# RL6955_IP_SVD register map
Vendor: Realtek
Registers are 32-bit, read-write, reset 0x0 unless marked. A register's access mark holds for its fields unless they carry their own. Offsets are from the block's base; [hi:lo] are bit positions; {n}, {i} and the like mark numbered series; <NAME> marks a mode.

## CAN0_REG
Base 0x41803000
Same registers: CAN1_REG 0x41804000
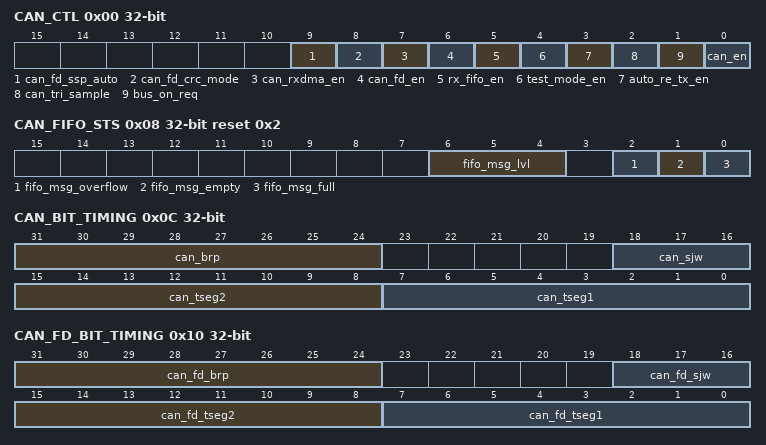
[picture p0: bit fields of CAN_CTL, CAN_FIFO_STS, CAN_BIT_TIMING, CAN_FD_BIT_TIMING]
0x00 CAN_CTL — CAN bus control register
  [9] can_fd_ssp_auto — automatic calculat ssp delay, ssp = second sample point
  [8] can_fd_crc_mode — crc mode select * 0: ISO crc * 1: non-ISO crc
  [7] can_rxdma_en — rx dma enable
  [6] can_fd_en — enable CAN FD protocol
  [5] rx_fifo_en — rx fifo function enable
  [4] test_mode_en — test mode enable, for lbk or silent mode use
  [3] auto_re_tx_en — auto re-transmission enabled
  [2] can_tri_sample — triple sample mode
  [1] bus_on_req — request to bus_on
  [0] can_en — can enable
0x04 CAN_STS ro — CAN bus status
  [0] bus_on_state — bus state * 1 means the can module is already bus on * 0 means the can module is busoff
0x08 CAN_FIFO_STS ro reset 0x2 — CAN bus FIFO status
  [6:4] fifo_msg_lvl — rx fifo message level
  [2] fifo_msg_overflow — rx fifo overflow
  [1] fifo_msg_empty — rx fifo empty
  [0] fifo_msg_full — rx fifo full
0x0C CAN_BIT_TIMING — CAN2.0 bit timing
  [31:24] can_brp — CAN bit timing perscaler = <$bit:can_brp>+1
  [18:16] can_sjw — SJW length = <$bit:can_sjw>
  [15:8] can_tseg2 — TSEG2 length = <$bit:can_tseg2+1>
  [7:0] can_tseg1 — TSEG1 length = <$bit:can_tseg1+1>
0x10 CAN_FD_BIT_TIMING — CAN FD DATA field bit timing
  [31:24] can_fd_brp — CAN bit timing perscaler = <$bit:can_fd_brp>+1
  [18:16] can_fd_sjw — SJW length = <$bit:can_fd_sjw>
  [15:8] can_fd_tseg2 — TSEG2 length = <$bit:can_fd_tseg2+1>
  [7:0] can_fd_tseg1 — TSEG1 length = <$bit:can_fd_tseg1>+1
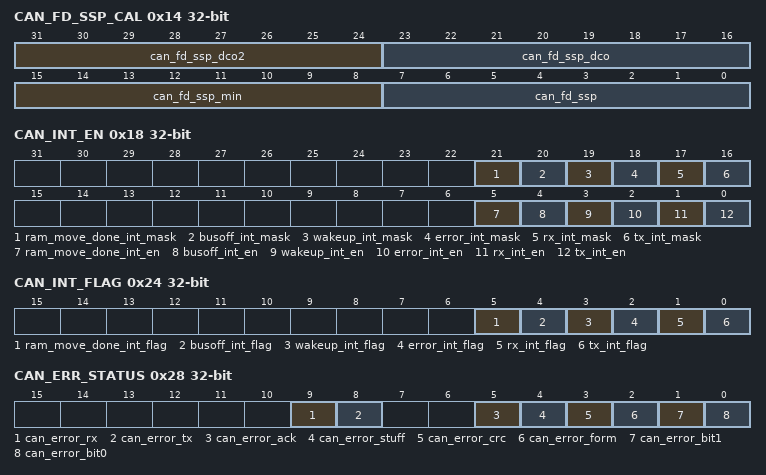
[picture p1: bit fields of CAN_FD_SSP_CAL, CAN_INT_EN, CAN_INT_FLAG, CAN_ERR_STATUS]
0x14 CAN_FD_SSP_CAL — CAN FD SSP configuration
  [31:24] can_fd_ssp_dco2 — delay compensation offset2
  [23:16] can_fd_ssp_dco — delay compensation offset
  [15:8] can_fd_ssp_min — minimum of ssp from start of one bit, only functional when can_fd_ssp_auto set
  [7:0] can_fd_ssp — ssp position, delay from start of one bit, if automatic calculation is enabled, the field will update after calculation
0x18 CAN_INT_EN — CAN interrupt control
  [21] ram_move_done_int_mask — ram move done interrupt mask 1: mask 0: unmask
  [20] busoff_int_mask — wakeup interrupt mask 1: mask 0: unmask
  [19] wakeup_int_mask — wakeup interrupt mask 1: mask 0: unmask
  [18] error_int_mask — error interrupt mask 1: mask 0: unmask
  [17] rx_int_mask — rx interrupt mask 1: mask 0: unmask
  [16] tx_int_mask — tx interrupt mask 1: mask 0: unmask
  [5] ram_move_done_int_en — ram move done interrupt enable
  [4] busoff_int_en — wakeup interrupt enbale
  [3] wakeup_int_en — wakeup interrupt enbale
  [2] error_int_en — error interrupt enable
  [1] rx_int_en — rx interrupt enable
  [0] tx_int_en — tx interrupt enable
0x1C CAN_MB_RXINT_EN — CAN rx interrupt for message buffers
  [15:0] can_mb_rxint_en — rx interrupt enable for each message buffer
0x20 CAN_MB_TXINT_EN — CAN tx interrupt for message buffers
  [15:0] can_mb_txint_en — tx interrupt enable for each message buffer
0x24 CAN_INT_FLAG ro — CAN interrupt flags
  [5] ram_move_done_int_flag — data move from register to CAN IP internal RAM finished interupt, move from RAM to register done will NOT generate interrupt, write one to clear
  [4] busoff_int_flag — busoff interrupt flag, write one to clear
  [3] wakeup_int_flag — wakeup interrupt flag, write one to clear
  [2] error_int_flag — error interrupt flag, write to clear
  [1] rx_int_flag — rx interrupt flag, write to clear
  [0] tx_int_flag — tx interrupt flag, write to clear
0x28 CAN_ERR_STATUS ro — CAN error status
  [9] can_error_rx — can rx error flag
  [8] can_error_tx — can tx error flag
  [5] can_error_ack — latest error is ack error
  [4] can_error_stuff — latest error is stuff error
  [3] can_error_crc — latest error is ctc error
  [2] can_error_form — latest error is form error
  [1] can_error_bit1 — latest error is bit1 error, tx=1 but rx=0
  [0] can_error_bit0 — latest error is bit0 error, tx=0 but rx=1
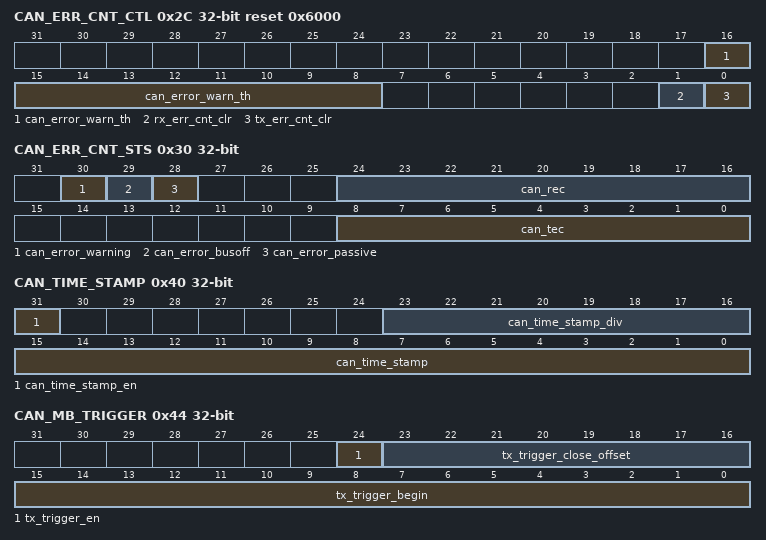
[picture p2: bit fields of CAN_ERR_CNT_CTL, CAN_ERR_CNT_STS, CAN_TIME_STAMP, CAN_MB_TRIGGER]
0x2C CAN_ERR_CNT_CTL access per field reset 0x6000 — CAN bus error counter control
  [16:8] can_error_warn_th rw — error counter warning threshold, programable, default 96. NOTES: 0~127 is availaible to both TEC and REC, 128~255 is only available to TEC
  [1] rx_err_cnt_clr wo — write 1 to clear can_rec
  [0] tx_err_cnt_clr wo — write 1 to clear can_tec
0x30 CAN_ERR_CNT_STS ro — CAN bus error counter status
  [30] can_error_warning — error counter arrive at warning threshold
  [29] can_error_busoff — error counter arrive at bus off level
  [28] can_error_passive — error counter arrive at error passive level
  [24:16] can_rec — receive error count
  [8:0] can_tec — transmit error count
0x34 CAN_TX_ERROR_FLAG ro — CAN tx error flag for each message buffe
  [15:0] can_tx_error_flag — indicate which message tx buffer have error detected, cpu can write 1 to clear
0x38 CAN_TX_DONE ro — CAN tx done for message buffers
  [15:0] can_tx_done — tx done for each message buffer
0x3C CAN_RX_DONE ro — CAN rx done for message buffers
  [15:0] can_rx_done — rx done for each message buffer
0x40 CAN_TIME_STAMP access per field — Timestamp function
  [31] can_time_stamp_en rw — time stamp function enable and time stamp counter start
  [23:16] can_time_stamp_div rw — timer stamp conter prescalar
  [15:0] can_time_stamp ro — time stamp counter value, up count
0x44 CAN_MB_TRIGGER — CAN tx trigger by timer configuration
  [24] tx_trigger_en — End of message buffer base address in RAM
  [23:16] tx_trigger_close_offset — end of trigger time = <$bit:tx_trigger_begin> + <$bit:tx_trigger_close_offset>
  [15:0] tx_trigger_begin — start of trigger time
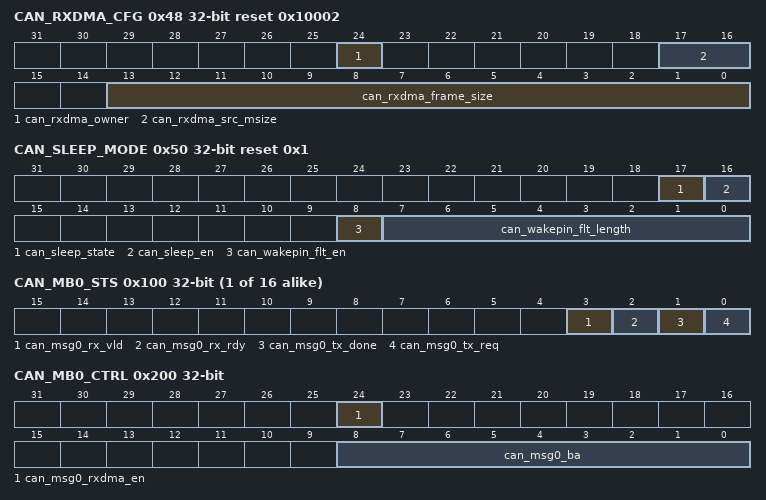
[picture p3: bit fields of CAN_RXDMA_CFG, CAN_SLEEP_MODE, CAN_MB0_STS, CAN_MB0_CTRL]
0x48 CAN_RXDMA_CFG access per field reset 0x10002 — RX dma configuration
  [24] can_rxdma_owner rw — can rxdma owner is : 0:GDMA 1:CAN
  [17:16] can_rxdma_src_msize rw — rx dma burst size: 'b00: dma burst size=1 'b01: dma burst size=4 'b10: dma burst size=8 'b11: dma burst size=16
  [13:0] can_rxdma_frame_size ro — can rx dma data frame size = ceil(<rx_dma_data bytes number>/4 ), for example: rx_dma_data is 9~12 bytes, frame size is 3
0x4C CAN_RX_DMA_DATA ro — Register for dma access message buffe
  [31:0] can_rx_dma_data — For DMA read received data
0x50 CAN_SLEEP_MODE access per field reset 0x1 — sleep mode request and wakeup pin digital filter
  [17] can_sleep_state ro — can is sleep or not 1: is 0: isn't
  [16] can_sleep_en rw — can sleep enable 1:request can to sleep mode 0:wakeup can
  [8] can_wakepin_flt_en rw — wakeup pin digital filter enable
  [7:0] can_wakepin_flt_length rw — wakeup pin digital filter length
0x54 CAN_TEST — test configuration
  [1:0] can_test_cfg — 2b'00: silence_mode 2b'01: external loopback mode (enable can_tx_so ) 2b'10: internal loopback mode (can_tx_so tie 1) 2b'11: reserved
{0x100+4i} CAN_MB{i}_STS ro (i=0..15)
  [3] can_msg{i}_rx_vld — new message have been received in the message buffer
  [2] can_msg{i}_rx_rdy — the message buffer is ready for receiving a new message
  [1] can_msg{i}_tx_done — tx message in the message buffer finish sending
  [0] can_msg{i}_tx_req — tx message is pending for transmit
0x200 CAN_MB0_CTRL
  [24] can_msg0_rxdma_en — dma enable when the message buffer used as rx
  [8:0] can_msg0_ba — message buffer base address in RAM
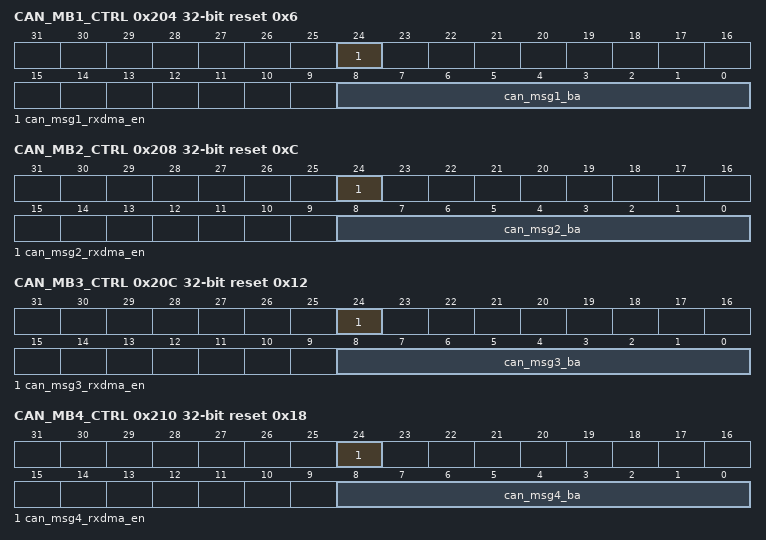
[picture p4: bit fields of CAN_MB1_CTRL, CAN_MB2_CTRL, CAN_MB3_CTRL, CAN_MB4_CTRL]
0x204 CAN_MB1_CTRL reset 0x6
  [24] can_msg1_rxdma_en — dma enable when the message buffer used as rx
  [8:0] can_msg1_ba — message buffer base address in RAM
0x208 CAN_MB2_CTRL reset 0xC
  [24] can_msg2_rxdma_en — dma enable when the message buffer used as rx
  [8:0] can_msg2_ba — message buffer base address in RAM
0x20C CAN_MB3_CTRL reset 0x12
  [24] can_msg3_rxdma_en — dma enable when the message buffer used as rx
  [8:0] can_msg3_ba — message buffer base address in RAM
0x210 CAN_MB4_CTRL reset 0x18
  [24] can_msg4_rxdma_en — dma enable when the message buffer used as rx
  [8:0] can_msg4_ba — message buffer base address in RAM
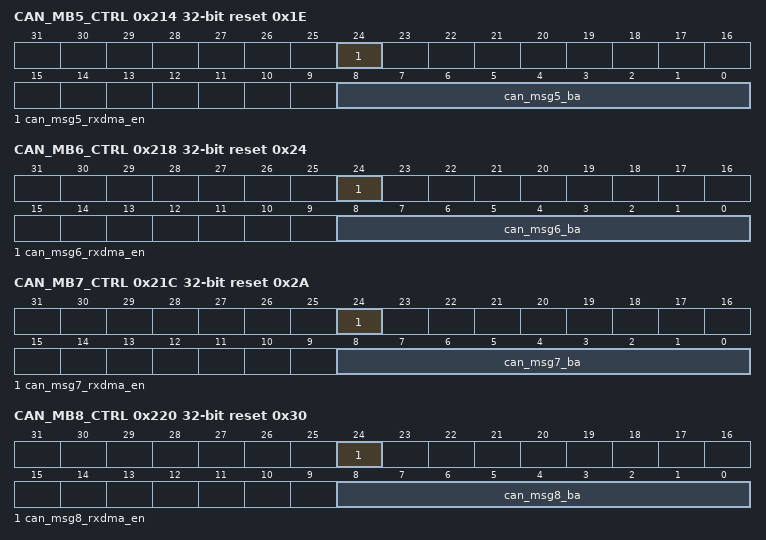
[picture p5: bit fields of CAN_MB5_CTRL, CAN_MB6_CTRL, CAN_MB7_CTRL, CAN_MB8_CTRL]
0x214 CAN_MB5_CTRL reset 0x1E
  [24] can_msg5_rxdma_en — dma enable when the message buffer used as rx
  [8:0] can_msg5_ba — message buffer base address in RAM
0x218 CAN_MB6_CTRL reset 0x24
  [24] can_msg6_rxdma_en — dma enable when the message buffer used as rx
  [8:0] can_msg6_ba — message buffer base address in RAM
0x21C CAN_MB7_CTRL reset 0x2A
  [24] can_msg7_rxdma_en — dma enable when the message buffer used as rx
  [8:0] can_msg7_ba — message buffer base address in RAM
0x220 CAN_MB8_CTRL reset 0x30
  [24] can_msg8_rxdma_en — dma enable when the message buffer used as rx
  [8:0] can_msg8_ba — message buffer base address in RAM
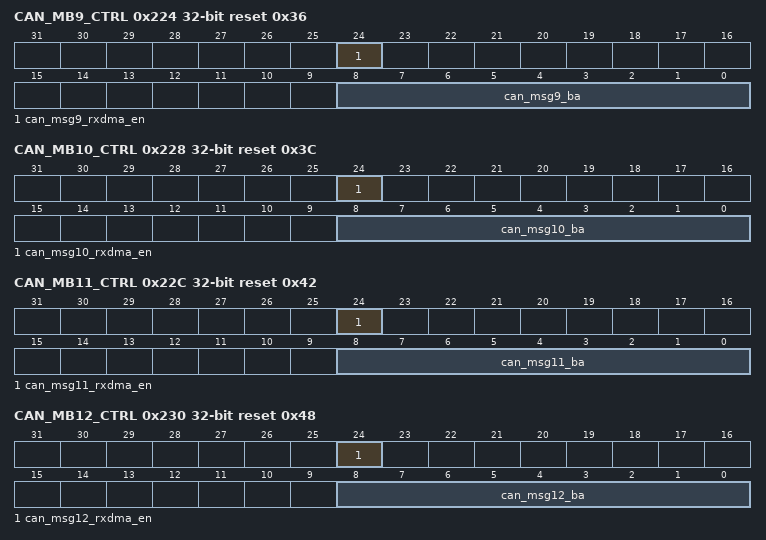
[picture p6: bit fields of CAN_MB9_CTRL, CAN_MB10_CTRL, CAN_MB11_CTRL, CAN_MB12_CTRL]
0x224 CAN_MB9_CTRL reset 0x36
  [24] can_msg9_rxdma_en — dma enable when the message buffer used as rx
  [8:0] can_msg9_ba — message buffer base address in RAM
0x228 CAN_MB10_CTRL reset 0x3C
  [24] can_msg10_rxdma_en — dma enable when the message buffer used as rx
  [8:0] can_msg10_ba — message buffer base address in RAM
0x22C CAN_MB11_CTRL reset 0x42
  [24] can_msg11_rxdma_en — dma enable when the message buffer used as rx
  [8:0] can_msg11_ba — message buffer base address in RAM
0x230 CAN_MB12_CTRL reset 0x48
  [24] can_msg12_rxdma_en — dma enable when the message buffer used as rx
  [8:0] can_msg12_ba — message buffer base address in RAM
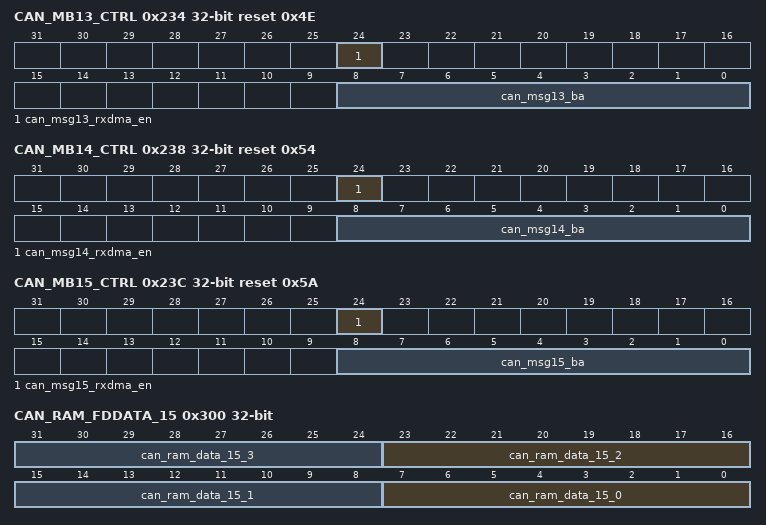
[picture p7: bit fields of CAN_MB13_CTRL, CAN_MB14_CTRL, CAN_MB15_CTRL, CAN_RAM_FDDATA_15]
0x234 CAN_MB13_CTRL reset 0x4E
  [24] can_msg13_rxdma_en — dma enable when the message buffer used as rx
  [8:0] can_msg13_ba — message buffer base address in RAM
0x238 CAN_MB14_CTRL reset 0x54
  [24] can_msg14_rxdma_en — dma enable when the message buffer used as rx
  [8:0] can_msg14_ba — message buffer base address in RAM
0x23C CAN_MB15_CTRL reset 0x5A
  [24] can_msg15_rxdma_en — dma enable when the message buffer used as rx
  [8:0] can_msg15_ba — message buffer base address in RAM
0x2F0 CAN_MB_BA_END reset 0x60
  [9:0] can_msg_ba_end — End of message buffer base address in RAM
0x300 CAN_RAM_FDDATA_15 — CAN data
  [8n+7:8n] can_ram_data_15_{n} (n=0..3) — data_byte 4*15+{n}
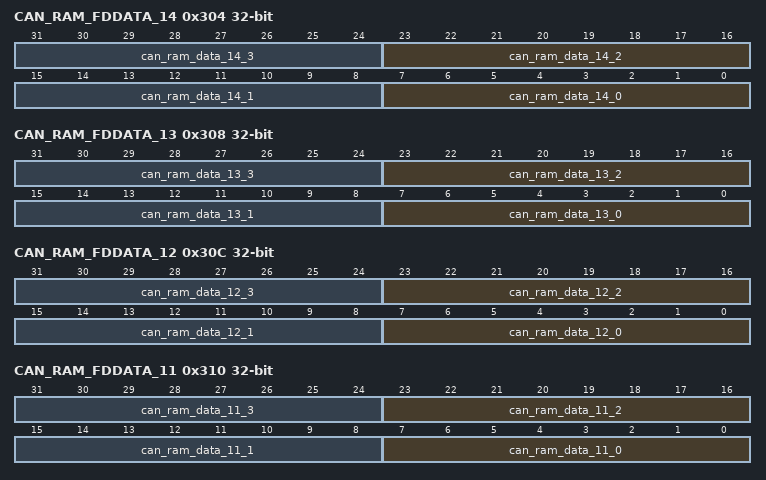
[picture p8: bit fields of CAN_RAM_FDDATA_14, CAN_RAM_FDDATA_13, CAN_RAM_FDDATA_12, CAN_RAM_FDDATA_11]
0x304 CAN_RAM_FDDATA_14 — CAN data
  [8n+7:8n] can_ram_data_14_{n} (n=0..3) — data_byte 4*14+{n}
0x308 CAN_RAM_FDDATA_13 — CAN data
  [8n+7:8n] can_ram_data_13_{n} (n=0..3) — data_byte 4*13+{n}
0x30C CAN_RAM_FDDATA_12 — CAN data
  [8n+7:8n] can_ram_data_12_{n} (n=0..3) — data_byte 4*12+{n}
0x310 CAN_RAM_FDDATA_11 — CAN data
  [8n+7:8n] can_ram_data_11_{n} (n=0..3) — data_byte 4*11+{n}
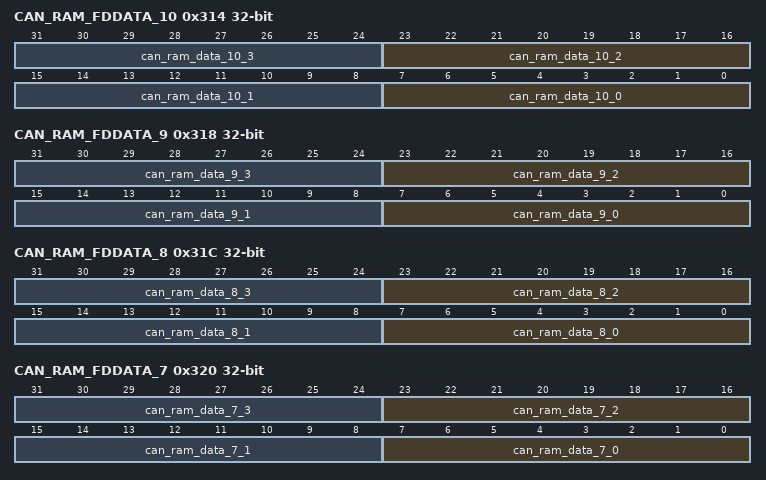
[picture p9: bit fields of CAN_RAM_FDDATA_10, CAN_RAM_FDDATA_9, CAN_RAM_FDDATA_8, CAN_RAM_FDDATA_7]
0x314 CAN_RAM_FDDATA_10 — CAN data
  [8n+7:8n] can_ram_data_10_{n} (n=0..3) — data_byte 4*10+{n}
0x318 CAN_RAM_FDDATA_9 — CAN data
  [8n+7:8n] can_ram_data_9_{n} (n=0..3) — data_byte 4*9+{n}
0x31C CAN_RAM_FDDATA_8 — CAN data
  [8n+7:8n] can_ram_data_8_{n} (n=0..3) — data_byte 4*8+{n}
0x320 CAN_RAM_FDDATA_7 — CAN data
  [8n+7:8n] can_ram_data_7_{n} (n=0..3) — data_byte 4*7+{n}
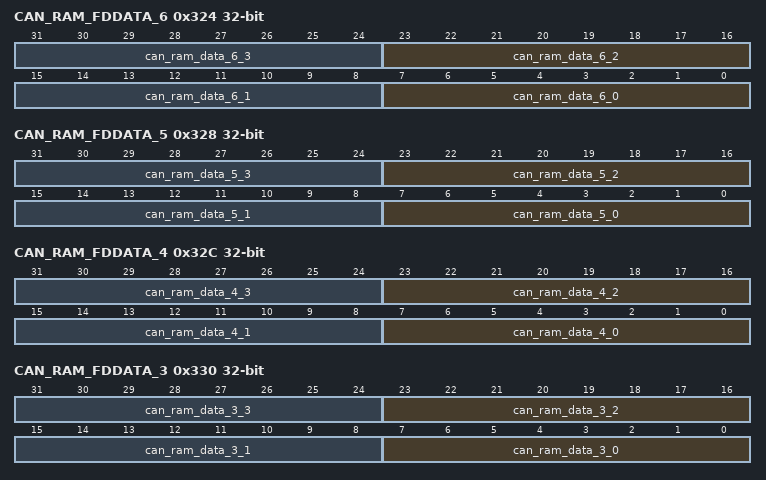
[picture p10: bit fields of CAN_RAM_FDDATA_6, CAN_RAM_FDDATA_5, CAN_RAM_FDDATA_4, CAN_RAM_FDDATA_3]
0x324 CAN_RAM_FDDATA_6 — CAN data
  [8n+7:8n] can_ram_data_6_{n} (n=0..3) — data_byte 4*6+{n}
0x328 CAN_RAM_FDDATA_5 — CAN data
  [8n+7:8n] can_ram_data_5_{n} (n=0..3) — data_byte 4*5+{n}
0x32C CAN_RAM_FDDATA_4 — CAN data
  [8n+7:8n] can_ram_data_4_{n} (n=0..3) — data_byte 4*4+{n}
0x330 CAN_RAM_FDDATA_3 — CAN data
  [8n+7:8n] can_ram_data_3_{n} (n=0..3) — data_byte 4*3+{n}
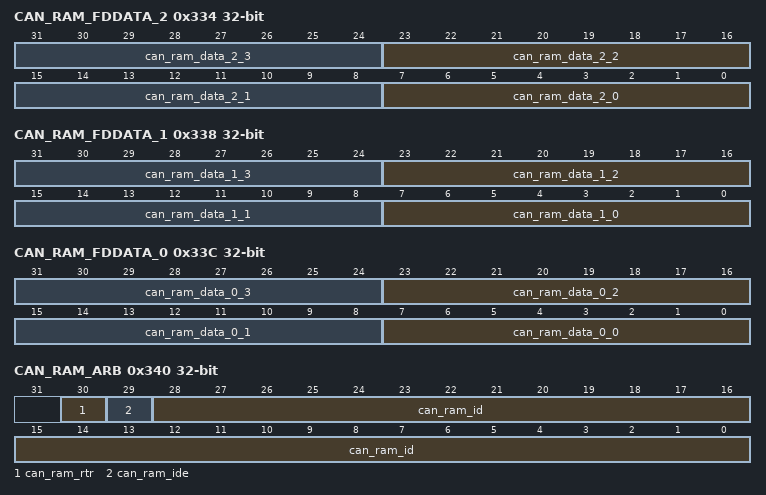
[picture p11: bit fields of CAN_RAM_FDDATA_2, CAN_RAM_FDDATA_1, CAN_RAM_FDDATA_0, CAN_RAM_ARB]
0x334 CAN_RAM_FDDATA_2 — CAN data
  [8n+7:8n] can_ram_data_2_{n} (n=0..3) — data_byte 4*2+{n}
0x338 CAN_RAM_FDDATA_1 — CAN data
  [8n+7:8n] can_ram_data_1_{n} (n=0..3) — data_byte 4*1+{n}
0x33C CAN_RAM_FDDATA_0 — CAN data
  [8n+7:8n] can_ram_data_0_{n} (n=0..3) — data_byte 4*0+{n}
0x340 CAN_RAM_ARB — CAN message buffer arb field configuration
  [30] can_ram_rtr — can frame RTR bit, determine DATA or REMOTE frame
  [29] can_ram_ide — can frame IDE bit, determine standard or extend format
  [28:0] can_ram_id — can frame ID, including high 11 bit standard ID and low 18 bit extend ID
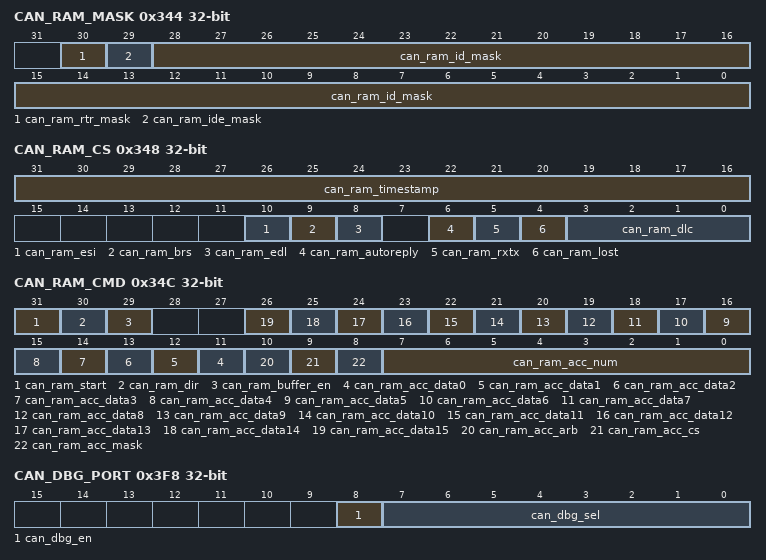
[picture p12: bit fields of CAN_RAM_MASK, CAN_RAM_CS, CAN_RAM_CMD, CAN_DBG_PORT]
0x344 CAN_RAM_MASK — CAN message buffer arb field mask configuration
  [30] can_ram_rtr_mask — can frame RTR mask, 0 means don't care, 1 means the bit should match
  [29] can_ram_ide_mask — can frame IDE mask, 0 means don't care, 1 means the bit should match
  [28:0] can_ram_id_mask — can frame ID mask, 0 means the ID bit in CAN_RAM_ARB don't care, 1 means the bit should match.
0x348 CAN_RAM_CS — CAN message type control
  [31:16] can_ram_timestamp — the received message time stamp
  [10] can_ram_esi — FD frame esi bit, indicate error passive of message sending node, read bit, should always write 0, hardware automatic fill
  [9] can_ram_brs — FD frame brs bit, indicate switch bit timing
  [8] can_ram_edl — FD frame edl bit, indicate it's a FD frame
  [6] can_ram_autoreply — set the message buffer with remote frame auto reply function
  [5] can_ram_rxtx — can frame RX or TX, 0 is for RX, 1 is for TX
  [4] can_ram_lost — data have lost in the read buffer, means more than one frame have beed received since last read; only avaliable when rx FIFO is disabled
  [3:0] can_ram_dlc — data length
0x34C CAN_RAM_CMD — CAN message buffer access control
  [31] can_ram_start — start to exchange data with RAM, the bit will clear automatically after the data change is finshed.
  [30] can_ram_dir — 0 is for read from RAM to CAN_RAM_* registers, 1 is for write from CAN_RAM_* to RAM
  [29] can_ram_buffer_en — enable the can_ram_acc_num specified message buffer for rx/tx
  [n+11] can_ram_acc_data{n} (n=0..15) — access CAN_RAM_DATA_{n} field, the field will exchange with RAM space
  [10] can_ram_acc_arb — access CAN_RAM_ARB field, the field will exchange with RAM space
  [9] can_ram_acc_cs — access CAN_RAM_CS field, the field will exchange with RAM space
  [8] can_ram_acc_mask — access CAN_RAM_MASK field, the field will exchange with RAM space
  [7:0] can_ram_acc_num — access buffer number
0x3F8 CAN_DBG_PORT — debug register
  [8] can_dbg_en — debug port enable
  [7:0] can_dbg_sel — debug port selection
0x3FC CAN_DUMMY — dummy register
  [31:0] dummy — rsvd for hw
